# max32572 register map
Vendor: Maxim-Integrated; Series: ARMCM4; File version: 1.0
CPU: CM4 r2p1, little endian, MPU, FPU, 3 interrupt priority bits
Registers are 32-bit, read-write, reset 0x0 unless marked. A register's access mark holds for its fields unless they carry their own. Offsets are from the block's base; [hi:lo] are bit positions; {n}, {i} and the like mark numbered series; 'fields as' and 'values as' point back to an identical list.

## GCR — Global Control Registers.
Base 0x40000000
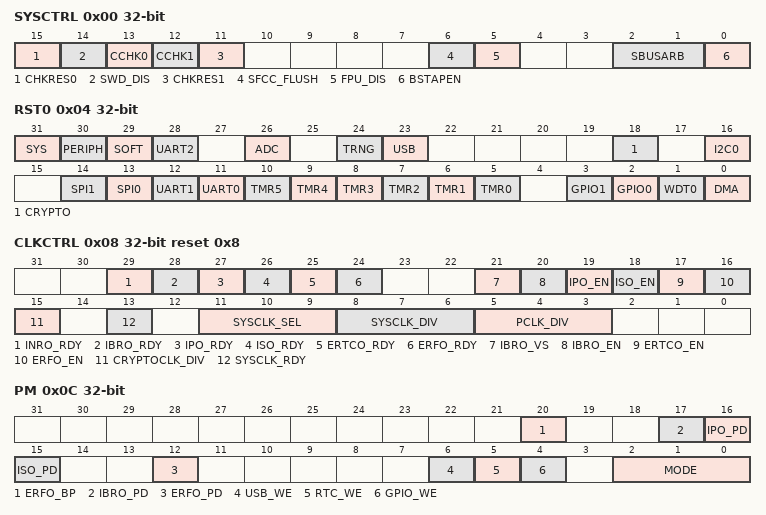
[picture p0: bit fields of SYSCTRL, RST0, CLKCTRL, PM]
0x00 SYSCTRL (reset mask 0xFFFFFFFE) — System Control.
  [15] CHKRES0 — ROM Checksum Result. This bit is only valid when CHKRD=1.
    0=pass (ROM Checksum Correct.); 1=fail (ROM Checksum Fail.)
  [14] SWD_DIS — Serial Wire Debug Disable.
  [13] CCHK0 — Compute ROM0 Checksum. This bit is self-cleared when calculation is completed. Once set, software clearing this bit is ignored and the bit will remain set until the operation is completed.
    0=complete (No operation/complete.); 1=Start operation
  [12] CCHK1 — Compute CPU1 ROM1 Checksum
  [11] CHKRES1 — Result of CPU1 ROM1 Checksum.
  [6] SFCC_FLUSH — Code Cache Flush. This bit is used to flush the code caches and the instruction buffer of the Cortex-M4.
    0=Normal Code Cache Operation; 1=flush (Code Caches and CPU instruction buffer are flushed)
  [5] FPU_DIS — Cortex M4 Floating Point Disable This bit is used to disable the floating-point unit of the Cortex-M4.
  [2:1] SBUSARB — System bus abritration scheme. These bits are used to select between Fixed-burst abritration and Round-Robin scheme. The Round-Robin scheme is selected by default. These bits are reset by the system reset.
    0=fix (Fixed Burst abritration.); 1=Round-robin scheme
  [0] BSTAPEN — Boundary Scan TAP enable. When enabled, the JTAG port is conneted to the Boundary Scan TAP instead of the ARM ICE.
    0=dis (Boundary Scan TAP port disabled.); 1=en (Boundary Scan TAP port enabled.)
0x04 RST0 — Reset.
  [all] fields
    0=reset_done (Reset complete.); 1=busy (Starts Reset or indicates reset in progress.)
  [31] SYS — System Reset. Setting this bit to 1 resets the CPU core and all peripherals, including the watchdog timer.
  [30] PERIPH — Peripheral Reset. Setting this bit to 1 resets all peripherals. The CPU core, the watchdog timer, and all GPIO pins are unaffected by this reset.
  [29] SOFT — Soft Reset. Setting this bit to 1 resets everything except the CPU and the watchdog timer.
  [28] UART2 — UART2 Reset. Setting this bit to 1 resets all UART 2 blocks.
  [26] ADC — ADC Reset.
  [24] TRNG — TRNG Reset.
  [23] USB — USB Reset.
  [18] CRYPTO — Crypto Reset.
  [16] I2C0 — I2C 0 Reset.
  [14] SPI1 — SPI 1 Reset. Setting this bit to 1 resets all SPI 1 blocks.
  [13] SPI0 — SPI 0 Reset. Setting this bit to 1 resets all SPI 0 blocks.
  [12] UART1 — UART 1 Reset. Setting this bit to 1 resets all UART 1 blocks.
  [11] UART0 — UART 0 Reset. Setting this bit to 1 resets all UART 0 blocks.
  [10] TMR5 — Timer5 Reset. Setting this bit to 1 resets Timer 5 blocks.
  [9] TMR4 — Timer4 Reset. Setting this bit to 1 resets Timer 4 blocks.
  [n+5] TMR{n} (n=0..3) — Timer {n} Reset. Setting this bit to 1 resets Timer {n} blocks.
  [3] GPIO1 — GPIO1 Reset. Setting this bit to 1 resets GPIO1 pins to their default states.
  [2] GPIO0 — GPIO0 Reset. Setting this bit to 1 resets GPIO0 pins to their default states.
  [1] WDT0 — Watchdog Timer 0 Reset.
  [0] DMA — DMA Reset.
0x08 CLKCTRL reset 0x8 — Clock Control.
  [29] INRO_RDY ro — 8 kHz Low Frequency Reference Clock Ready.
    0=not (Is not Ready.); 1=ready (Is Ready.)
  [28] IBRO_RDY ro — 7.3725 MHz HIRC Ready.
    0=not (Is not Ready.); 1=ready (Is Ready.)
  [27] IPO_RDY ro — 100 MHz Clock Ready.
    0=not (Is not Ready.); 1=ready (Is Ready.)
  [26] ISO_RDY ro — 60 MHz Oscillator Ready.
    0=not (Is not Ready.); 1=ready (Is Ready.)
  [25] ERTCO_RDY ro — 32 kHz Crystal Oscillator Ready
    0=not (Is not Ready.); 1=ready (Is Ready.)
  [24] ERFO_RDY ro — 32 MHz Oscillator Ready
    0=not (Is not Ready.); 1=ready (Is Ready.)
  [21] IBRO_VS — 7.3725 MHz High Frequency Internal Reference Clock Voltage Select. This register bit is used to select the power supply to the IBRO.
    0=VCore Supply; 1=1V (Dedicated 1V regulated supply.)
  [20] IBRO_EN — 7.3725 MHz Clock Enable.
    0=dis (Is Disabled.); 1=en (Is Enabled.)
  [19] IPO_EN — 100 MHz Clock Enable.
    0=dis (Is Disabled.); 1=en (Is Enabled.)
  [18] ISO_EN — 60 MHz Internal Oscillator Enable.
    0=dis (Is Disabled.); 1=en (Is Enabled.)
  [17] ERTCO_EN — 32 kHz Oscillator Enable.
    0=dis (Is Disabled.); 1=en (Is Enabled.)
  [16] ERFO_EN — 27 MHz Crystal Oscillator Enable.
    0=dis (Is Disabled.); 1=en (Is Enabled.)
  [15] CRYPTOCLK_DIV ro — Cryptographic clock divider
    0=non_div (The cryptographic accelerator clock is running in non-divided mode.); 1=div (The cryptographic accelerator clock is running in divided mode.)
  [13] SYSCLK_RDY ro — Clock Ready. This read only bit reflects whether the currently selected system clock source is running.
    0=busy (Switchover to the new clock source (as selected by CLKSEL) has not yet occurred.); 1=ready (System clock running from CLKSEL clock source.)
  [11:9] SYSCLK_SEL — Clock Source Select. This 3 bit field selects the source for the system clock.
    0=ISO (The internal 60 MHz oscillator is used for the system clock.); 2=ERFO (The external 32 MHz input is used for the system clock.); 3=INRO (8 kHz LIRC is used for the system clock.); 4=IPO (The internal 100 MHz oscillator is used for the system clock.); 5=IBRO (The internal 7.3725 MHz oscillator is used for the system clock.); 6=ERTCO (External 32 kHz input is used for the system clock.)
  [8:6] SYSCLK_DIV — Prescaler Select. This 3 bit field sets the system operating frequency by controlling the prescaler that divides the output of the PLL0.
    0=div1 (Divide by 1.); 1=div2 (Divide by 2.); 2=div4 (Divide by 4.); 3=div8 (Divide by 8.); 4=div16 (Divide by 16.); 5=div32 (Divide by 32.); 6=div64 (Divide by 64.); 7=div128 (Divide by 128.)
  [5:3] PCLK_DIV — PCLK Divider.
    0=div1 (Divide by 1.); 1=div2 (Divide by 2.); 2=div4 (Divide by 4.); 3=div8 (Divide by 8.)
0x0C PM — Power Management.
  [20] ERFO_BP — 27MHz Oscillator Bypass.
  [17] IBRO_PD — 7.3725 MHz power down. This bit selects 7.3725 MHz clock power state in DEEPSLEEP mode.
    0=active (Mode is Active.); 1=deepsleep (Powered down in DEEPSLEEP.)
  [16] IPO_PD — 100 MHz power down. This bit selects 100 MHz clock power state in DEEPSLEEP mode.
    values as IBRO_PD
  [15] ISO_PD — 60 MHz power down. This bit selects the 60 MHz clock power state in DEEPSLEEP mode.
    values as IBRO_PD
  [12] ERFO_PD — 27 MHz power down. This bit selects the 27 MHz clock power state in DEEPSLEEP mode.
    values as IBRO_PD
  [6] USB_WE — USB Wake Up Enable. This bit enables USB IRQ as wakeup source
    0=dis (Wake Up Disable.); 1=en (Wake Up Enable.)
  [5] RTC_WE — RTC Alarm Wake Up Enable. This bit enables RTC alarm as wakeup source. If enabled, the desired RTC alarm must be configured via the RTC control registers.
    0=dis (Wake Up Disable.); 1=en (Wake Up Enable.)
  [4] GPIO_WE — GPIO Wake Up Enable. This bit enables all GPIO pins as potential wakeup sources. Any GPIO configured for wakeup is capable of causing an exit from IDLE or STANDBY modes when this bit is set.
    0=dis (Wake Up Disable.); 1=en (Wake Up Enable.)
  [2:0] MODE — Operating Mode. This two bit field selects the current operating mode for the device. Note that code execution only occurs during ACTIVE mode.
    0=Active Mode; 1=Sleep Mode; 2=DeepSleep Mode; 3=ShutDown Mode; 4=Backup Mode
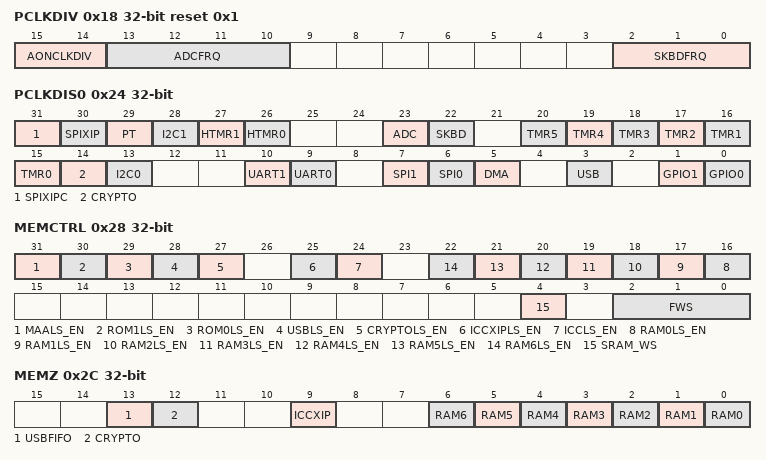
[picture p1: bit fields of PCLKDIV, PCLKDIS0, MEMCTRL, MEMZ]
0x18 PCLKDIV reset 0x1 — Peripheral Clock Divider.
  [15:14] AONCLKDIV — AON Clock Divider. These bits define the AON Domain Clock Divider.
    0=div4; 1=div8; 2=div16; 3=div32
  [13:10] ADCFRQ — ADC clock Frequency. These bits define the ADC clock frequency. fADC = fPCLK / (ADCFRQ)
  [2:0] SKBDFRQ — GCR Frequency Indicator for Secure Keyboard.
0x24 PCLKDIS0 — Peripheral Clock Disable.
  [all] fields
    0=en (enable it.); 1=dis (disable it.)
  [31] SPIXIPC — SPI XIPC Clock Disable.
  [30] SPIXIP — SPI XIP Clock Disable.
  [29] PT — Pluse Train Clock Disable.
  [28] I2C1 — I2C 1 Clock Disable.
  [27] HTMR1 — High Speed Timer 1 Clock Disable.
  [26] HTMR0 — High Speed Timer 0 Clock Disable.
  [23] ADC — ADC Clock Disable.
  [22] SKBD — Secure Keypad Clock Disable.
  [n+15] TMR{n} (n=0..5) — Timer {n} Clock Disable.
  [14] CRYPTO — Crypto Clock Disable.
  [13] I2C0 — I2C 0 Clock Disable.
  [10] UART1 — UART 1 Clock Disable.
  [9] UART0 — UART 0 Clock Disable.
  [7] SPI1 — SPI 1 Clock Disable.
  [6] SPI0 — SPI 0 Clock Disable.
  [5] DMA — DMA Clock Disable.
  [3] USB — USB Clock Disable.
  [1] GPIO1 — GPIO1 Clock Disable.
  [0] GPIO0 — GPIO0 Clock Disable.
0x28 MEMCTRL — Memory Clock Control Register.
  [31] MAALS_EN — MAA Light Sleep Mode.
    0=active (RAM is active.); 1=light_sleep (RAM is in Light Sleep mode.)
  [30] ROM1LS_EN — ROM1 Light Sleep Mode.
    values as MAALS_EN
  [29] ROM0LS_EN — ROM0 Light Sleep Mode.
    values as MAALS_EN
  [28] USBLS_EN — USB FIFO Light Sleep Mode.
    values as MAALS_EN
  [27] CRYPTOLS_EN — MEU RAM Light Sleep Mode.
    values as MAALS_EN
  [25] ICCXIPLS_EN — ICACHE-XIP RAM Light Sleep Mode.
    values as MAALS_EN
  [24] ICCLS_EN — ICache RAM Light Sleep Mode.
    values as MAALS_EN
  [n+16] RAM{n}LS_EN (n=0..6) — System RAM {n} Light Sleep Mode.
    values as MAALS_EN
  [4] SRAM_WS — SYSRAM WS Select.
  [2:0] FWS — Flash Wait State. These bits define the number of wait-state cycles per Flash data read access. Minimum wait state is 2.
0x2C MEMZ — Memory Zeroize Control.
  [all] fields
    0=nop (No operation/complete.); 1=Start operation
  [13] USBFIFO — USB FIFO Zeroization.
  [12] CRYPTO — MEU Memory Zeroization.
  [9] ICCXIP — Internal ICC XIP Data and Tag RAM Zeroization.
  [n] RAM{n} (n=0..6) — System RAM Block {n} Zeroization.
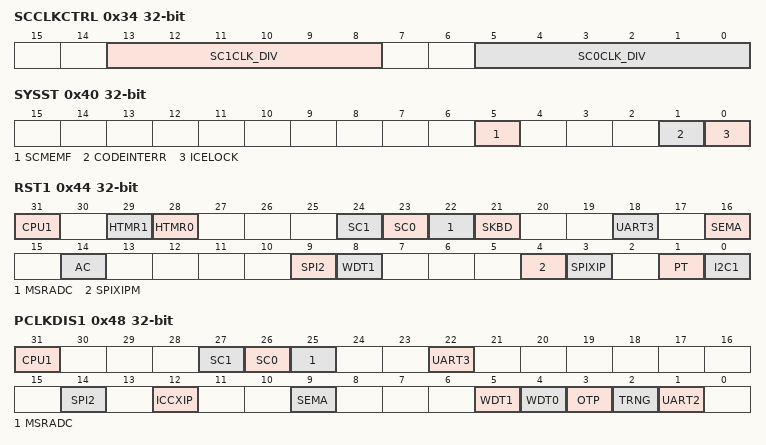
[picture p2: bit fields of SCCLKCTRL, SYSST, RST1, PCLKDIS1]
0x34 SCCLKCTRL — Smart Card Clock Control.
  [13:8] SC1CLK_DIV — Smart Card1 Clock Divider
  [5:0] SC0CLK_DIV — Smart Card0 Clock Divider
0x40 SYSST — System Status Register.
  [5] SCMEMF — System Cache Memory Fault Flag. This bit indicates a memory fault has occured in the System Cache while receiving data from the Hyperbus Interface.
    0=Normal Operating Condition; 1=Memory Fault
  [1] CODEINTERR — Code Integrity Error Flag. This bit indicates a code integrity error has occured in XiP interface.
    0=Normal Operating Condition; 1=Code Integrity Error
  [0] ICELOCK — ARM ICE Lock Status.
    0=unlocked (ICE is unlocked.); 1=locked (ICE is locked.)
0x44 RST1 — Reset 1.
  [all] fields
    on read: 0=reset_done (Reset complete.); 1=busy (Starts reset or indicates reset in progress.)
  [31] CPU1 — CPU1 Reset.
  [29] HTMR1 — HTIMER1 Reset.
  [28] HTMR0 — HTIMER0 Reset.
  [24] SC1 — SC1 Reset.
  [23] SC0 — SC0 Reset.
  [22] MSRADC — MSRADC Reset.
  [21] SKBD — SKBD Reset.
  [18] UART3 — UART3 Reset.
  [16] SEMA — Semaphore Reset.
  [14] AC — Auto-Cal Reset.
  [9] SPI2 — SPI2 Reset.
  [8] WDT1 — WDT1 Reset.
  [4] SPIXIPM — SPI XIP Master Reset.
  [3] SPIXIP — SPI XIPF Reset.
  [1] PT — PT Reset.
  [0] I2C1 — I2C1 Reset.
0x48 PCLKDIS1 — Peripheral Clock Disable.
  [all] fields
    0=en (Clock enabled to the peripheral.); 1=dis (Clock disabled to the peripheral.)
  [31] CPU1 — CPU1 Clock Disable.
  [27] SC1 — SC1 Clock Disable.
  [26] SC0 — SC0 Clock Disable.
  [25] MSRADC — MSRADC Clock Disable.
  [22] UART3 — UART3 Clock Disable.
  [14] SPI2 — SPI2 Clock Disable.
  [12] ICCXIP — ICC XIP Clock Disable.
  [9] SEMA — Semaphore Disable.
  [5] WDT1 — Watchdog 1 Clock Disable.
  [4] WDT0 — Watchdog 0 Clock Disable.
  [3] OTP — OTP Clock Disable.
  [2] TRNG — TRNG Clock Disable.
  [1] UART2 — UART2 Clock Disable.
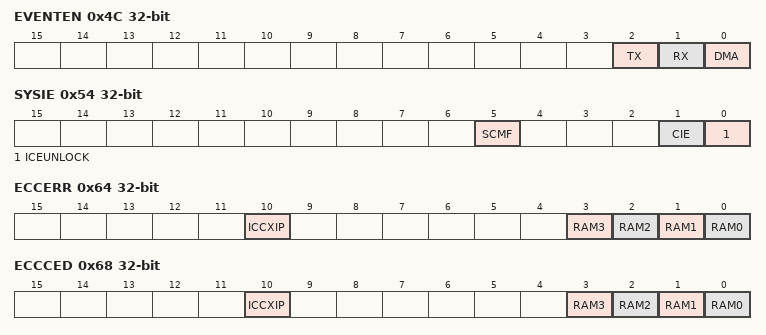
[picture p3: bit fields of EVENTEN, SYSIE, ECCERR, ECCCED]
0x4C EVENTEN — Event Enable Register.
  [2] TX — Enable TXEV pin event. When this bit is set, TXEV event from the CPU is output to GPIO1.9.
  [1] RX — Enable RXEV pin event. When this bit is set, RXEV event from the CPU is output to GPIO1.9.
  [0] DMA — Enable DMA event. When this bit is set, a DMA event will cause an RXEV event to wake the CPU from WFE sleep mode.
0x50 REVISION ro
  [15:0] REVISION — Manufacturer Chip Revision.
0x54 SYSIE — System Status Interrupt Enable Register.
  [all] fields
    0=dis (disabled.); 1=en (enabled.)
  [5] SCMF — System Cache Memory Fault Interrupt Enable.
  [1] CIE — Code Integrity Error Interrupt Enable.
  [0] ICEUNLOCK — ARM ICE Unlock Interrupt Enable.
0x58 IPOCNT — IPO Warmup Count Register.
  [9:0] WMUPCNT
0x64 ECCERR — ECC Error Register
  [10] ICCXIP — ECC System ICACHEXIP Error Flag. Write 1 to clear.
  [n] RAM{n} (n=0..3) — ECC System RAM{n} Error Flag. Write 1 to clear.
0x68 ECCCED — ECC Not Double Error Detect Register
  fields as ECCERR
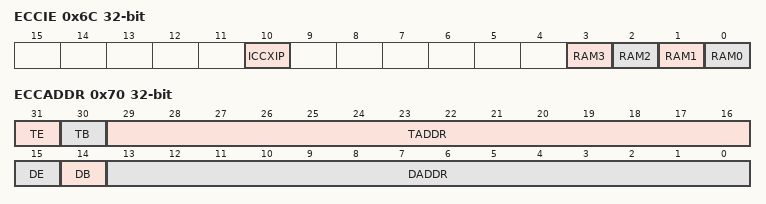
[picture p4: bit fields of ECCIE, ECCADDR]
0x6C ECCIE — ECC IRQ Enable Register
  fields as ECCERR
0x70 ECCADDR — ECC Error Address Register
  [31] TE — Tag Error Flag.
  [30] TB — Tag Bank.
  [29:16] TADDR — Address of Error in Tag RAM.
  [15] DE — Data Error Flag.
  [14] DB — Data Bank,
  [13:0] DADDR — Address of Error in Data RAM.
